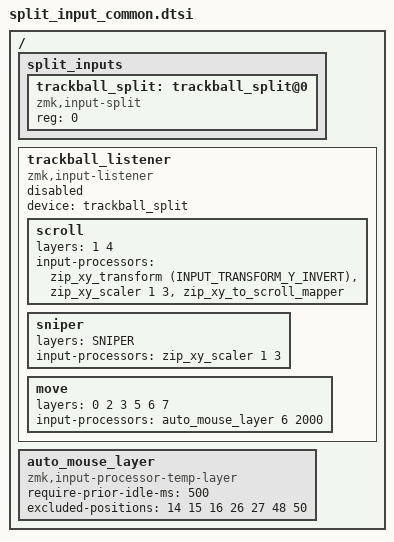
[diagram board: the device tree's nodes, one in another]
#include <dt-bindings/zmk/input_transform.h>
#include <input/processors.dtsi>

#define DEF 0
#define MOUSE 6
#define SNIPER 8

/ {
  split_inputs {
    #address-cells = <1>;
    #size-cells = <0>;

    trackball_split: trackball_split@0 {
      compatible = "zmk,input-split";
      reg = <0>;
    };
  };

  trackball_listener: trackball_listener {
    compatible = "zmk,input-listener";
    status = "disabled";
    device = <&trackball_split>;

    scroll {
      layers = <1 4>;
      input-processors = <&zip_xy_transform (INPUT_TRANSFORM_Y_INVERT)>, <&zip_xy_scaler 1 3>, <&zip_xy_to_scroll_mapper>;
    };

    sniper {
      layers = <SNIPER>;
      input-processors = <&zip_xy_scaler 1 3>;  // 0.33x speed for precision
    };

    move {
      layers = <0 2 3 5 6 7>;
      input-processors = <&auto_mouse_layer 6 2000>;
    };
  };

  auto_mouse_layer: auto_mouse_layer {
    compatible = "zmk,input-processor-temp-layer";
    #input-processor-cells = <2>;
    require-prior-idle-ms = <500>;
    excluded-positions = <14 15 16 26 27 48 50>;
  };
};
